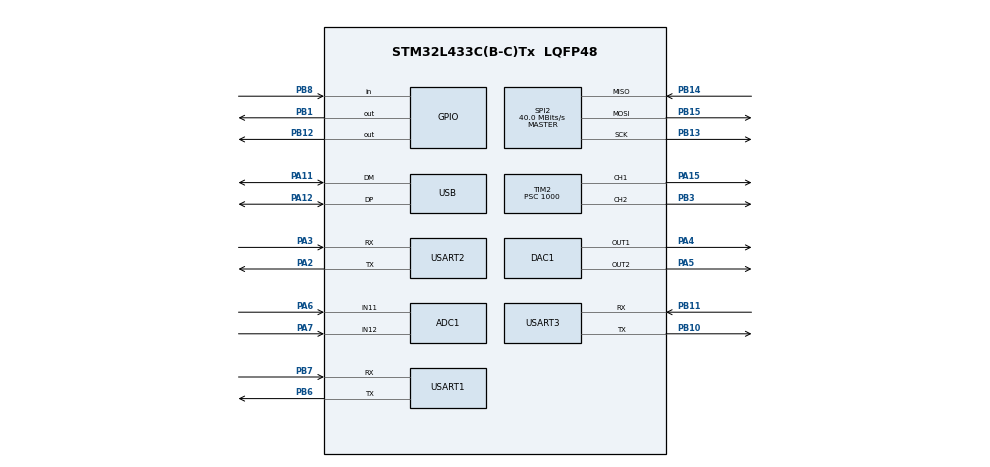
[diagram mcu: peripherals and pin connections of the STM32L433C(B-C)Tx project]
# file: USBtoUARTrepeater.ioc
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ADC1.Channel-0\#ChannelRegularConversion=ADC_CHANNEL_11
ADC1.NbrOfConversionFlag=1
ADC1.OffsetNumber-0\#ChannelRegularConversion=ADC_OFFSET_NONE
ADC1.Rank-0\#ChannelRegularConversion=1
ADC1.SamplingTime-0\#ChannelRegularConversion=ADC_SAMPLETIME_2CYCLES_5
ADC1.master=1
DAC1.DAC_Channel-DAC_OUT2=DAC_CHANNEL_2
Dma.Request0=USART1_RX
Dma.Request1=USART1_TX
Dma.Request2=USART2_RX
Dma.Request3=USART2_TX
Dma.Request4=USART3_RX
Dma.Request5=USART3_TX
Dma.USART1_RX.0.Direction=DMA_PERIPH_TO_MEMORY
Dma.USART1_RX.0.Instance=DMA1_Channel5
Dma.USART1_RX.0.MemDataAlignment=DMA_MDATAALIGN_BYTE
Dma.USART1_RX.0.MemInc=DMA_MINC_ENABLE
Dma.USART1_RX.0.Mode=DMA_NORMAL
Dma.USART1_RX.0.PeriphDataAlignment=DMA_PDATAALIGN_BYTE
Dma.USART1_RX.0.PeriphInc=DMA_PINC_DISABLE
Dma.USART1_RX.0.Priority=DMA_PRIORITY_HIGH
Dma.USART1_TX.1.Direction=DMA_MEMORY_TO_PERIPH
Dma.USART1_TX.1.Instance=DMA1_Channel4
Dma.USART1_TX.1.MemDataAlignment=DMA_MDATAALIGN_BYTE
Dma.USART1_TX.1.MemInc=DMA_MINC_ENABLE
Dma.USART1_TX.1.Mode=DMA_NORMAL
Dma.USART1_TX.1.PeriphDataAlignment=DMA_PDATAALIGN_BYTE
Dma.USART1_TX.1.PeriphInc=DMA_PINC_DISABLE
Dma.USART1_TX.1.Priority=DMA_PRIORITY_HIGH
Dma.USART2_RX.2.Direction=DMA_PERIPH_TO_MEMORY
Dma.USART2_RX.2.Instance=DMA1_Channel6
Dma.USART2_RX.2.MemDataAlignment=DMA_MDATAALIGN_BYTE
Dma.USART2_RX.2.MemInc=DMA_MINC_ENABLE
Dma.USART2_RX.2.Mode=DMA_NORMAL
Dma.USART2_RX.2.PeriphDataAlignment=DMA_PDATAALIGN_BYTE
Dma.USART2_RX.2.PeriphInc=DMA_PINC_DISABLE
Dma.USART2_RX.2.Priority=DMA_PRIORITY_HIGH
Dma.USART2_TX.3.Direction=DMA_MEMORY_TO_PERIPH
Dma.USART2_TX.3.Instance=DMA1_Channel7
Dma.USART2_TX.3.MemDataAlignment=DMA_MDATAALIGN_BYTE
Dma.USART2_TX.3.MemInc=DMA_MINC_ENABLE
Dma.USART2_TX.3.Mode=DMA_NORMAL
Dma.USART2_TX.3.PeriphDataAlignment=DMA_PDATAALIGN_BYTE
Dma.USART2_TX.3.PeriphInc=DMA_PINC_DISABLE
Dma.USART2_TX.3.Priority=DMA_PRIORITY_HIGH
Dma.USART3_RX.4.Direction=DMA_PERIPH_TO_MEMORY
Dma.USART3_RX.4.Instance=DMA1_Channel3
Dma.USART3_RX.4.MemDataAlignment=DMA_MDATAALIGN_BYTE
Dma.USART3_RX.4.MemInc=DMA_MINC_ENABLE
Dma.USART3_RX.4.Mode=DMA_NORMAL
Dma.USART3_RX.4.PeriphDataAlignment=DMA_PDATAALIGN_BYTE
Dma.USART3_RX.4.PeriphInc=DMA_PINC_DISABLE
Dma.USART3_RX.4.Priority=DMA_PRIORITY_HIGH
Dma.USART3_TX.5.Direction=DMA_MEMORY_TO_PERIPH
Dma.USART3_TX.5.Instance=DMA1_Channel2
Dma.USART3_TX.5.MemDataAlignment=DMA_MDATAALIGN_BYTE
Dma.USART3_TX.5.MemInc=DMA_MINC_ENABLE
Dma.USART3_TX.5.Mode=DMA_NORMAL
Dma.USART3_TX.5.PeriphDataAlignment=DMA_PDATAALIGN_BYTE
Dma.USART3_TX.5.PeriphInc=DMA_PINC_DISABLE
Dma.USART3_TX.5.Priority=DMA_PRIORITY_HIGH
FREERTOS.INCLUDE_vTaskDelayUntil=1
FREERTOS.Tasks01=MainTask,0,256,StartMainTask,Default,NULL,Dynamic,NULL,NULL;USBCtrlTask,-3,1024,StartUSBCtrlTask,Default,NULL,Dynamic,NULL,NULL;ServoCtrlTask,2,1024,StartServoCtrlTask,Default,NULL,Dynamic,NULL,NULL
FREERTOS.configTOTAL_HEAP_SIZE=16384
Mcu.Family=STM32L4
Mcu.Name=STM32L433C(B-C)Tx
Mcu.Package=LQFP48
NVIC.DMA1_Channel2_IRQn=true\:5\:0\:false\:false\:true\:true\:false\:true
NVIC.DMA1_Channel3_IRQn=true\:5\:0\:false\:false\:true\:true\:false\:true
NVIC.DMA1_Channel4_IRQn=true\:5\:0\:false\:false\:true\:true\:false\:true
NVIC.DMA1_Channel5_IRQn=true\:5\:0\:false\:false\:true\:true\:false\:true
NVIC.DMA1_Channel6_IRQn=true\:5\:0\:false\:false\:true\:true\:false\:true
NVIC.DMA1_Channel7_IRQn=true\:5\:0\:false\:false\:true\:true\:false\:true
NVIC.PriorityGroup=NVIC_PRIORITYGROUP_4
NVIC.TIM7_IRQn=true\:0\:0\:false\:false\:true\:false\:false\:true
NVIC.TimeBase=TIM7_IRQn
NVIC.TimeBaseIP=TIM7
NVIC.USART1_IRQn=true\:5\:0\:true\:false\:true\:true\:true\:true
NVIC.USART2_IRQn=true\:5\:0\:false\:false\:true\:true\:true\:true
NVIC.USART3_IRQn=true\:5\:0\:false\:false\:true\:true\:true\:true
NVIC.USB_IRQn=true\:5\:0\:false\:false\:true\:true\:false\:true
PA11.Mode=Device
PA11.Signal=USB_DM
PA12.Mode=Device
PA12.Signal=USB_DP
PA13\ (JTMS-SWDIO).Mode=Serial_Wire
PA13\ (JTMS-SWDIO).Signal=SYS_JTMS-SWDIO
PA14\ (JTCK-SWCLK).Mode=Serial_Wire
PA14\ (JTCK-SWCLK).Signal=SYS_JTCK-SWCLK
PA15\ (JTDI).Signal=S_TIM2_CH1
PA2.Mode=Asynchronous
PA2.Signal=USART2_TX
PA3.Mode=Asynchronous
PA3.Signal=USART2_RX
PA4.Signal=COMP_DAC11_group
PA5.Signal=COMP_DAC12_group
PA6.Signal=ADCx_IN11
PA7.Signal=ADCx_IN12
PB1.Signal=GPIO_Output
PB10.Mode=Asynchronous
PB10.Signal=USART3_TX
PB11.Mode=Asynchronous
PB11.Signal=USART3_RX
PB12.Signal=GPIO_Output
PB13.Mode=Full_Duplex_Master
PB13.Signal=SPI2_SCK
PB14.Mode=Full_Duplex_Master
PB14.Signal=SPI2_MISO
PB15.Mode=Full_Duplex_Master
PB15.Signal=SPI2_MOSI
PB3\ (JTDO-TRACESWO).Signal=S_TIM2_CH2
PB6.GPIO_PuPd=GPIO_PULLUP
PB6.Mode=Asynchronous
PB6.Signal=USART1_TX
PB7.GPIO_PuPd=GPIO_PULLUP
PB7.Mode=Asynchronous
PB7.Signal=USART1_RX
PB8.Signal=GPIO_Input
ProjectManager.HeapSize=0x200
ProjectManager.StackSize=0x400
ProjectManager.TargetToolchain=STM32CubeIDE
RCC.ADCFreq_Value=80000000
RCC.AHBFreq_Value=80000000
RCC.APB1Freq_Value=80000000
RCC.APB1TimFreq_Value=80000000
RCC.APB2Freq_Value=80000000
RCC.APB2TimFreq_Value=80000000
RCC.CK48CLockSelection=RCC_USBCLKSOURCE_HSI48
RCC.CortexFreq_Value=80000000
RCC.HCLKFreq_Value=80000000
RCC.HSE_VALUE=8000000
RCC.HSI48_VALUE=48000000
RCC.HSI_VALUE=16000000
RCC.LSE_VALUE=32768
RCC.MSI_VALUE=4000000
RCC.PLLN=10
RCC.PLLSAI1N=10
RCC.PLLSourceVirtual=RCC_PLLSOURCE_HSI
RCC.SYSCLKFreq_VALUE=80000000
RCC.SYSCLKSource=RCC_SYSCLKSOURCE_PLLCLK
RCC.USBFreq_Value=48000000
RCC.VCOOutputFreq_Value=160000000
SH.ADCx_IN11.0=ADC1_IN11,IN11-Single-Ended
SH.ADCx_IN12.0=ADC1_IN12,IN12-Single-Ended
SH.COMP_DAC11_group.0=DAC1_OUT1,DAC_OUT1
SH.COMP_DAC12_group.0=DAC1_OUT2,DAC_OUT2
SH.S_TIM2_CH1.0=TIM2_CH1,PWM Generation1 CH1
SH.S_TIM2_CH2.0=TIM2_CH2,PWM Generation2 CH2
SPI2.BaudRatePrescaler=SPI_BAUDRATEPRESCALER_2
SPI2.CalculateBaudRate=40.0 MBits/s
SPI2.DataSize=SPI_DATASIZE_8BIT
SPI2.Direction=SPI_DIRECTION_2LINES
SPI2.Mode=SPI_MODE_MASTER
SPI2.VirtualType=VM_MASTER
TIM16.Prescaler=8000
TIM2.Channel-PWM\ Generation1\ CH1=TIM_CHANNEL_1
TIM2.Channel-PWM\ Generation2\ CH2=TIM_CHANNEL_2
TIM2.Period=80000
TIM2.Prescaler=1000
USART1.Parity=PARITY_EVEN
USART1.VirtualMode-Asynchronous=VM_ASYNC
USART1.WordLength=WORDLENGTH_9B
USART2.VirtualMode-Asynchronous=VM_ASYNC
USART2.WordLength=WORDLENGTH_8B
USART3.VirtualMode-Asynchronous=VM_ASYNC
USB_DEVICE.APP_RX_DATA_SIZE=256
USB_DEVICE.APP_TX_DATA_SIZE=256
USB_DEVICE.CLASS_NAME_FS=CDC
USB_DEVICE.VirtualMode=Cdc
USB_DEVICE.VirtualModeFS=Cdc_FS
VP_FREERTOS_VS_CMSIS_V1.Mode=CMSIS_V1
VP_SYS_VS_tim7.Mode=TIM7
VP_TIM16_VS_ClockSourceINT.Mode=Enable_Timer
VP_USB_DEVICE_VS_USB_DEVICE_CDC_FS.Mode=CDC_FS
board=custom

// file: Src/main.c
/* USER CODE BEGIN Header */
/**
  ******************************************************************************
  * @file           : main.c
  * @brief          : Main program body
  ******************************************************************************
  * @attention
  *
  * <h2><center>&copy; Copyright (c) 2019 STMicroelectronics.
  * All rights reserved.</center></h2>
  *
  * This software component is licensed by ST under BSD 3-Clause license,
  * the "License"; You may not use this file except in compliance with the
  * License. You may obtain a copy of the License at:
  *                        opensource.org/licenses/BSD-3-Clause
  *
  ******************************************************************************
  */
/* USER CODE END Header */

#include "main.h"
#include "cmsis_os.h"
#include "adc.h"
#include "dac.h"
#include "dma.h"
#include "spi.h"
#include "tim.h"
#include "usart.h"
#include "usb_device.h"
#include "gpio.h"

/* USER CODE BEGIN Includes */
#include "usbd_cdc_if.h"
#include <string.h>
/* USER CODE END Includes */

void SystemClock_Config(void);
void MX_FREERTOS_Init(void);

int main(void)
{

  /* MCU Configuration--------------------------------------------------------*/

  /* Reset of all peripherals, Initializes the Flash interface and the Systick. */
  HAL_Init();

  /* Configure the system clock */
  SystemClock_Config();

  /* Initialize all configured peripherals */
  MX_GPIO_Init();
  MX_DMA_Init();
  MX_ADC1_Init();
  MX_DAC1_Init();
  MX_SPI2_Init();
  MX_TIM2_Init();
  MX_USART1_UART_Init();
  MX_USART2_UART_Init();
  MX_USART3_UART_Init();
  MX_TIM16_Init();
  /* USER CODE BEGIN 2 */
  Link_USART_and_DMA();
  /* USER CODE END 2 */

  /* Call init function for freertos objects (in freertos.c) */
  MX_FREERTOS_Init();

  /* Start scheduler */
  osKernelStart();

  /* We should never get here as control is now taken by the scheduler */

  /* Infinite loop */
  while (1)
  {

  }
}

void SystemClock_Config(void)
{
  LL_FLASH_SetLatency(LL_FLASH_LATENCY_4);

  if(LL_FLASH_GetLatency() != LL_FLASH_LATENCY_4)
  {
  Error_Handler();
  }
  LL_PWR_SetRegulVoltageScaling(LL_PWR_REGU_VOLTAGE_SCALE1);
  LL_RCC_HSI_Enable();

   /* Wait till HSI is ready */
  while(LL_RCC_HSI_IsReady() != 1)
  {

  }
  LL_RCC_HSI_SetCalibTrimming(16);
  LL_RCC_HSI48_Enable();

   /* Wait till HSI48 is ready */
  while(LL_RCC_HSI48_IsReady() != 1)
  {

  }
  LL_RCC_PLL_ConfigDomain_SYS(LL_RCC_PLLSOURCE_HSI, LL_RCC_PLLM_DIV_1, 10, LL_RCC_PLLR_DIV_2);
  LL_RCC_PLL_EnableDomain_SYS();
  LL_RCC_PLL_Enable();

   /* Wait till PLL is ready */
  while(LL_RCC_PLL_IsReady() != 1)
  {

  }
  LL_RCC_PLLSAI1_ConfigDomain_ADC(LL_RCC_PLLSOURCE_HSI, LL_RCC_PLLM_DIV_1, 10, LL_RCC_PLLSAI1R_DIV_2);
  LL_RCC_PLLSAI1_EnableDomain_ADC();
  LL_RCC_PLLSAI1_Enable();

   /* Wait till PLLSAI1 is ready */
  while(LL_RCC_PLLSAI1_IsReady() != 1)
  {

  }
  LL_RCC_SetSysClkSource(LL_RCC_SYS_CLKSOURCE_PLL);

   /* Wait till System clock is ready */
  while(LL_RCC_GetSysClkSource() != LL_RCC_SYS_CLKSOURCE_STATUS_PLL)
  {

  }
  LL_RCC_SetAHBPrescaler(LL_RCC_SYSCLK_DIV_1);
  LL_RCC_SetAPB1Prescaler(LL_RCC_APB1_DIV_1);
  LL_RCC_SetAPB2Prescaler(LL_RCC_APB2_DIV_1);
  LL_SetSystemCoreClock(80000000);
  LL_RCC_SetUSARTClockSource(LL_RCC_USART1_CLKSOURCE_PCLK2);
  LL_RCC_SetUSARTClockSource(LL_RCC_USART2_CLKSOURCE_PCLK1);
  LL_RCC_SetUSARTClockSource(LL_RCC_USART3_CLKSOURCE_PCLK1);
  LL_RCC_SetUSBClockSource(LL_RCC_USB_CLKSOURCE_HSI48);
  LL_RCC_SetADCClockSource(LL_RCC_ADC_CLKSOURCE_PLLSAI1);
}

void HAL_TIM_PeriodElapsedCallback(TIM_HandleTypeDef *htim)
{
  if (htim->Instance == TIM7) {
    HAL_IncTick();
  }
}

void Error_Handler(void)
{
}

/************************ (C) COPYRIGHT STMicroelectronics *****END OF FILE****/

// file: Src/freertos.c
/* USER CODE BEGIN Header */
/**
  ******************************************************************************
  * File Name          : freertos.c
  * Description        : Code for freertos applications
  ******************************************************************************
  * @attention
  *
  * <h2><center>&copy; Copyright (c) 2019 STMicroelectronics.
  * All rights reserved.</center></h2>
  *
  * This software component is licensed by ST under Ultimate Liberty license
  * SLA0044, the "License"; You may not use this file except in compliance with
  * the License. You may obtain a copy of the License at:
  *                             www.st.com/SLA0044
  *
  ******************************************************************************
  */
/* USER CODE END Header */

#include "FreeRTOS.h"
#include "task.h"
#include "main.h"
#include "cmsis_os.h"

/* USER CODE BEGIN Includes */
#include "wrapper_main.hpp"
/* USER CODE END Includes */

osThreadId MainTaskHandle;
osThreadId USBCtrlTaskHandle;
osThreadId ServoCtrlTaskHandle;

void StartMainTask(void const * argument);
void StartUSBCtrlTask(void const * argument);
void StartServoCtrlTask(void const * argument);

extern void MX_USB_DEVICE_Init(void);
void MX_FREERTOS_Init(void); /* (MISRA C 2004 rule 8.1) */

void MX_FREERTOS_Init(void) {

  /* Create the thread(s) */
  /* definition and creation of MainTask */
  osThreadDef(MainTask, StartMainTask, osPriorityNormal, 0, 256);
  MainTaskHandle = osThreadCreate(osThread(MainTask), NULL);

  /* definition and creation of USBCtrlTask */
  osThreadDef(USBCtrlTask, StartUSBCtrlTask, osPriorityIdle, 0, 1024);
  USBCtrlTaskHandle = osThreadCreate(osThread(USBCtrlTask), NULL);

  /* definition and creation of ServoCtrlTask */
  osThreadDef(ServoCtrlTask, StartServoCtrlTask, osPriorityHigh, 0, 1024);
  ServoCtrlTaskHandle = osThreadCreate(osThread(ServoCtrlTask), NULL);

}

void StartMainTask(void const * argument)
{

  /* init code for USB_DEVICE */
  MX_USB_DEVICE_Init();

  /* USER CODE BEGIN StartMainTask */
  	  maintask_cpp();
  /* USER CODE END StartMainTask */
}

void StartUSBCtrlTask(void const * argument)
{
  /* USER CODE BEGIN StartUSBCtrlTask */
	USBCtrltask_cpp();
  /* USER CODE END StartUSBCtrlTask */
}

void StartServoCtrlTask(void const * argument)
{
  /* USER CODE BEGIN StartServoCtrlTask */
	ServoCtrltask_cpp();
  /* USER CODE END StartServoCtrlTask */
}

/************************ (C) COPYRIGHT STMicroelectronics *****END OF FILE****/
